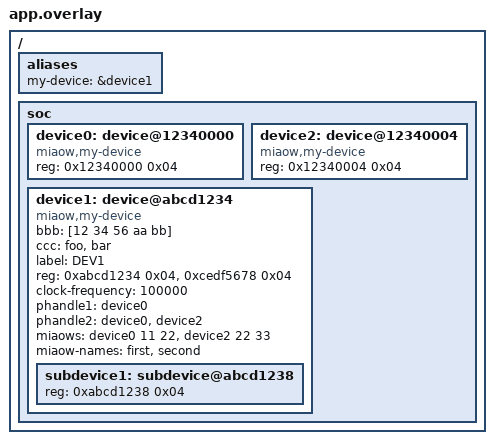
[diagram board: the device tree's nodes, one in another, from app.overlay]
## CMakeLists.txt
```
# SPDX-License-Identifier: Apache-2.0

cmake_minimum_required(VERSION 3.20.0)
set(BOARD fk743m5_xih6)
set(BOARD_FLASH_RUNNER jlink)
set(BOARD_DEBUG_RUNNER jlink)
set(BOARD_RUNNER_ARGS_jlink
    "--loader=BankAddr=0x90000000&Loader=CLK@PF10_nCS@PG6_D0@PF8_D1@PF9_D2@PF7_D3@PF6"
    CACHE STRING "Extra J-Link runner args" FORCE)
find_package(Zephyr REQUIRED HINTS $ENV{ZEPHYR_BASE})
find_package(Python3 REQUIRED COMPONENTS Interpreter)

project(devicetree LANGUAGES C)
target_sources(app PRIVATE ${CMAKE_SOURCE_DIR}/src/main.c)

# The code below locates the git index file for this repository and adds it as a dependency for
# the application VERSION file so that if the repo has a new commit added, even if no files in
# the build have changed, the application version file will be regenerated with the new git commit
find_package(Git QUIET)
if(GIT_FOUND)
  execute_process(
    COMMAND ${GIT_EXECUTABLE} rev-parse --absolute-git-dir
    WORKING_DIRECTORY .
    OUTPUT_VARIABLE application_git_dir
    OUTPUT_STRIP_TRAILING_WHITESPACE
    ERROR_STRIP_TRAILING_WHITESPACE
    ERROR_VARIABLE stderr
    RESULT_VARIABLE return_code
  )
  # If there is an error e.g. it is not a git repo, we just silently ignore it and continue
  # without a dependency, this will be the case with freestanding applications.
  if(NOT return_code)
    if(NOT "${stderr}" STREQUAL "")
      message(WARNING "Application build version git rev-parse warned: ${stderr}")
    endif()

    set_property(TARGET app_version_h PROPERTY APP_VERSION_DEPENDS ${application_git_dir}/index)
  endif()
endif()

# Update VS Code debug settings via workspace setup script.
# Run this after final zephyr.elf is linked (not after app library build).
set(VSCODE_SETUP_SCRIPT ${ZEPHYR_BASE}/../.vscode/setup.py)
if(EXISTS ${VSCODE_SETUP_SCRIPT})
  get_filename_component(VSCODE_ARM_TOOLCHAIN_PATH ${CMAKE_GDB} DIRECTORY)

  set(VSCODE_JLINK_DEVICE "")
  set(VSCODE_JLINK_LOADER "")
  get_property(VSCODE_JLINK_ARGS GLOBAL PROPERTY BOARD_RUNNER_ARGS_jlink)

  foreach(arg IN LISTS VSCODE_JLINK_ARGS)
    if(arg MATCHES "^--device=(.*)$")
      set(VSCODE_JLINK_DEVICE ${CMAKE_MATCH_1})
    elseif(arg MATCHES "^--loader=(.*)$")
      set(VSCODE_JLINK_LOADER ${CMAKE_MATCH_1})
    endif()
  endforeach()

  if(VSCODE_JLINK_LOADER)
    set(VSCODE_JLINK_DEVICE_FULL "${VSCODE_JLINK_DEVICE}?${VSCODE_JLINK_LOADER}")
  else()
    set(VSCODE_JLINK_DEVICE_FULL ${VSCODE_JLINK_DEVICE})
  endif()

  set(VSCODE_SETUP_STAMP ${CMAKE_BINARY_DIR}/.vscode_setup.stamp)
  add_custom_command(
    OUTPUT ${VSCODE_SETUP_STAMP}
    COMMAND ${Python3_EXECUTABLE} ${VSCODE_SETUP_SCRIPT}
      --app-path ${CMAKE_CURRENT_SOURCE_DIR}
      --build-path ${CMAKE_BINARY_DIR}
      --toolchain-path ${VSCODE_ARM_TOOLCHAIN_PATH}
      --gdb-path ${CMAKE_GDB}
      --device ${VSCODE_JLINK_DEVICE_FULL}
      --launch-json ${ZEPHYR_BASE}/../.vscode/launch.json
    COMMAND ${CMAKE_COMMAND} -E touch ${VSCODE_SETUP_STAMP}
    DEPENDS ${CMAKE_BINARY_DIR}/zephyr/zephyr.elf ${VSCODE_SETUP_SCRIPT}
    COMMENT "Run .vscode/setup.py to update launch.json and build symlink"
    VERBATIM
  )
  add_custom_target(vscode_setup_symlink ALL DEPENDS ${VSCODE_SETUP_STAMP})
endif()
```

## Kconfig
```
# SPDX-License-Identifier: Apache-2.0

mainmenu "03-devicetree"

# Your application configuration options go here

# Sources Kconfig.zephyr in the Zephyr root directory.
#
# Note: All 'source' statements work relative to the Zephyr root directory (due
# to the $srctree environment variable being set to $ZEPHYR_BASE). If you want
# to 'source' relative to the current Kconfig file instead, use 'rsource' (or a
# path relative to the Zephyr root).
source "Kconfig.zephyr"

menu "My Application Settings"

endmenu
```

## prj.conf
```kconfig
CONFIG_STD_C23=y
CONFIG_GNU_C_EXTENSIONS=y
CONFIG_SPEED_OPTIMIZATIONS=y
CONFIG_STM32_ENABLE_DEBUG_SLEEP_STOP=y

CONFIG_FPU=y
CONFIG_GPIO=y

CONFIG_LOG=y
CONFIG_LOG_RUNTIME_FILTERING=y
CONFIG_LOG_BACKEND_SWO=y
CONFIG_LOG_BACKEND_SWO_FREQ_HZ=50000000

CONFIG_BINDESC=y
CONFIG_BINDESC_DEFINE=y
CONFIG_BINDESC_DEFINE_VERSION=y
CONFIG_BINDESC_KERNEL_VERSION_STRING=y
CONFIG_BINDESC_KERNEL_VERSION_MAJOR=y
CONFIG_BINDESC_KERNEL_VERSION_MINOR=y
CONFIG_BINDESC_KERNEL_VERSION_PATCHLEVEL=y
CONFIG_BINDESC_KERNEL_VERSION_NUMBER=y
CONFIG_BINDESC_KERNEL_BUILD_VERSION=y
CONFIG_BINDESC_APP_VERSION_STRING=y
CONFIG_BINDESC_APP_VERSION_MAJOR=y
CONFIG_BINDESC_APP_VERSION_MINOR=y
CONFIG_BINDESC_APP_VERSION_PATCHLEVEL=y
CONFIG_BINDESC_APP_VERSION_NUMBER=y
CONFIG_BINDESC_APP_BUILD_VERSION=y
CONFIG_BINDESC_DEFINE_BUILD_TIME=y
CONFIG_BINDESC_BUILD_TIME_YEAR=y
CONFIG_BINDESC_BUILD_TIME_MONTH=y
CONFIG_BINDESC_BUILD_TIME_DAY=y
CONFIG_BINDESC_BUILD_TIME_HOUR=y
CONFIG_BINDESC_BUILD_TIME_MINUTE=y
CONFIG_BINDESC_BUILD_TIME_SECOND=y
CONFIG_BINDESC_BUILD_TIME_UNIX=y
CONFIG_BINDESC_BUILD_DATE_TIME_STRING=y
CONFIG_BINDESC_BUILD_DATE_STRING=y
CONFIG_BINDESC_BUILD_TIME_STRING=y
CONFIG_BINDESC_DEFINE_HOST_INFO=y
CONFIG_BINDESC_HOST_NAME=y
CONFIG_BINDESC_C_COMPILER_NAME=y
CONFIG_BINDESC_C_COMPILER_VERSION=y
CONFIG_BINDESC_CXX_COMPILER_NAME=y
CONFIG_BINDESC_CXX_COMPILER_VERSION=y
CONFIG_BINDESC_READ=y
CONFIG_BINDESC_READ_RAM=y
CONFIG_BINDESC_READ_MEMORY_MAPPED_FLASH=y
CONFIG_BINDESC_READ_FLASH=y
```

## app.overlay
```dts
/ {
	aliases {
		my-device = &device1;
	};

	soc {
		device0: device@12340000 {
			compatible = "miaow,my-device";
			#miaow-cells = <2>;
			reg = <0x12340000 0x04>;
		};

		device2: device@12340004 {
			compatible = "miaow,my-device";
			#miaow-cells = <2>;
			reg = <0x12340004 0x04>;
		};

		device1: device@abcd1234 {
			#address-cells = <1>;
    			#size-cells = <1>;
			#miaow-cells = <2>;

			compatible = "miaow,my-device";
			bbb = [12 34 56 aa bb];
			ccc = "foo", "bar";
			
                        label = "DEV1";
			reg = <0xabcd1234 0x04>, <0xcedf5678 0x04>;
			status = "okay";
			clock-frequency = <100000>;

			phandle1 = <&device0>;
			phandle2 = <&device0 &device2>;
			miaows = <&device0 11 22>, <&device2 22 33>;
			miaow-names = "first", "second";
			
			subdevice1: subdevice@abcd1238 {
				#phandle-miaow-cells = <2>;
				reg = <0xabcd1238 0x04>;
			};
		};
	};
};
```

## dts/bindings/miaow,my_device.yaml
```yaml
description: My custom device
compatible: "miaow,my-device"
miaow-cells:
  - c1
  - c2

include: [base.yaml]

properties:
  bbb:
    type: uint8-array
    description: My custom byte array property
    required: false

  ccc:
    type: string-array
    description: My custom string array property
    required: false

  clock-frequency:
    type: int
    description: Clock frequency for the device
    required: false
  
  phandle1:
    type: phandle
    description: A phandle property pointing to another node
    required: false
  
  phandle2:
    type: phandles
    description: An array of phandles pointing to other nodes
    required: false
  
  miaows:
    type: phandle-array
    description: An array of phandles pointing to other nodes
    required: false
  
  miaow-names:
    type: string-array
    description: An array of named phandles pointing to other nodes
    required: false
```

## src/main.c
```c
/*
 * Copyright (C) 2026, Miaow - All Rights Reserved
 *
 * SPDX-License-Identifier: GPL-3.0-or-later
 */
#include <stdio.h>
#include <zephyr/kernel.h>
#include <zephyr/bindesc.h>
#include <zephyr/logging/log.h>
#include <zephyr/devicetree.h>

LOG_MODULE_REGISTER(03_devicetree, LOG_LEVEL_INF);

/* Define the device node using one of the following methods:
 * 1. DT_PATH: path to the device node in the device tree
 * 2. DT_NODELABEL: node label defined in the device tree
 * 3. DT_ALIAS: alias defined in the device tree for the node
 * 4. DT_INST: instance of a compatible device. instance have no gurantee to be stable
 *
 * Uncomment one of the following lines to define MY_DEVICE_NODE accordingly.
 */
#define MY_DEVICE_NODE DT_PATH(soc, device_abcd1234)
// #define MY_DEVICE_NODE DT_NODELABEL(device1)
// #define MY_DEVICE_NODE DT_ALIAS(my_device)
// #define MY_DEVICE_NODE DT_INST(0, miaow_my_device)
// #define MY_DEVICE_NODE DT_CHILD(DT_PATH(soc), device_abcd1234)
// #define MY_DEVICE_NODE DT_PARENT(DT_PATH(soc, device_abcd1234, subdevice_abcd1238))

/**
 * @brief Print the message of the day (MOTD) using built-in descriptors.
 *
 * This function retrieves and prints various build and host information
 * using built-in descriptors defined in the Zephyr build system. It includes
 * details about the Zephyr version, application version, build time, and host
 * information such as compiler details.
 */
void print_motd()
{
	/* Builtin descriptors */
	printk("Zephyr version %s\n\tmajor:minor %u:%u\n\tnumber %u\n\tpatch %u\n\tbuild %s\n", BINDESC_GET_STR(kernel_version_string),
		BINDESC_GET_UINT(kernel_version_major), BINDESC_GET_UINT(kernel_version_minor),
		BINDESC_GET_UINT(kernel_version_number), BINDESC_GET_UINT(kernel_version_patchlevel),
		BINDESC_GET_STR(kernel_build_version)
	);
	printk("App version %s\n\tmajor:minor %u:%u\n\tnumber %u\n\tpatch %u\n\tbuild %s\n", BINDESC_GET_STR(app_version_string),
		BINDESC_GET_UINT(app_version_major), BINDESC_GET_UINT(app_version_minor),
		BINDESC_GET_UINT(app_version_number), BINDESC_GET_UINT(app_version_patchlevel),
		BINDESC_GET_STR(app_build_version)
	);
	printk("Build time %s\n\tdate %s\n\ttime %s\n\tunix %u\n\tyear %u\n\tmonth %u\n\tday %u\n\thour %u\n\tminute %u\n\tsecond %u\n",
		BINDESC_GET_STR(build_date_time_string),
		BINDESC_GET_STR(build_date_string),
		BINDESC_GET_STR(build_time_string),
		BINDESC_GET_UINT(build_time_unix),
		BINDESC_GET_UINT(build_time_year), BINDESC_GET_UINT(build_time_month), BINDESC_GET_UINT(build_time_day),
		BINDESC_GET_UINT(build_time_hour), BINDESC_GET_UINT(build_time_minute), BINDESC_GET_UINT(build_time_second)
	);
	printk("Host info\n\thost %s\n\tcc %s %s\n\tc++ %s %s\n",
		BINDESC_GET_STR(host_name),
		BINDESC_GET_STR(c_compiler_name), BINDESC_GET_STR(c_compiler_version),
		BINDESC_GET_STR(cxx_compiler_name), BINDESC_GET_STR(cxx_compiler_version)
	);
}

/**
 * @brief Check for the presence of specific properties in the device node.
 */
void check_prop()
{
	printk("has prop clock_frequency: %d\n", DT_NODE_HAS_PROP(MY_DEVICE_NODE, clock_frequency));
	printk("has prop not_a_prop: %d\n", DT_NODE_HAS_PROP(MY_DEVICE_NODE, not_a_prop));
	printk("ccc prop has index 1: %d\n", DT_PROP_HAS_IDX(MY_DEVICE_NODE, ccc, 1));
	printk("ccc prop has index 2: %d\n", DT_PROP_HAS_IDX(MY_DEVICE_NODE, ccc, 2));
}

/**
 * @brief Retrieve and print properties of the device node.
 */
void get_prop()
{
	const char compatible[] = DT_PROP(MY_DEVICE_NODE, compatible);
	const char label[] = DT_PROP(MY_DEVICE_NODE, label);
	const int reg[] = DT_PROP(MY_DEVICE_NODE, reg);
	const char status[] = DT_PROP(MY_DEVICE_NODE, status);
	const unsigned char b[] = DT_PROP(MY_DEVICE_NODE, bbb);
	const size_t b_item_count = DT_PROP_LEN(MY_DEVICE_NODE, bbb);
	const char *const c[] = DT_PROP(MY_DEVICE_NODE, ccc);
	const size_t c_item_count = DT_PROP_LEN(MY_DEVICE_NODE, ccc);

	printk("compatible=%s\n", compatible);
	printk("label=%s\n", label);

	printk("reg[]=");
	for (size_t i = 0; i < ARRAY_SIZE(reg); i++)
		printk("0x%x, ", reg[i]);
	printk("\n");

	printk("status=%s\n", status);

	printk("b[]=");
	for (size_t i = 0; i < b_item_count; i++)
		printk("%x, ", (int)b[i]);
	printk("\n");

	printk("c[]=");
	for (size_t i = 0; i < c_item_count; i++)
		printk("%s ", c[i]);
	printk("\n");
}

/**
 * @brief Retrieve and print the 'reg' properties of the device node.
 */
void reg_prop()
{
	size_t reg_count = DT_NUM_REGS(MY_DEVICE_NODE);
	printk("Number of reg blocks = %d\n", reg_count);
	uint32_t addr[] = {DT_REG_ADDR_BY_IDX(MY_DEVICE_NODE, 0), DT_REG_ADDR_BY_IDX(MY_DEVICE_NODE, 1)};
	uint32_t size[] = {DT_REG_SIZE_BY_IDX(MY_DEVICE_NODE, 0), DT_REG_SIZE_BY_IDX(MY_DEVICE_NODE, 1)};
	printk("reg[0].addr = 0x%x, .size = 0x%x\n", addr[0], size[0]);
	printk("reg[1].addr = 0x%x, .size = 0x%x\n", addr[1], size[1]);
}

/**
 * @brief Retrieve a device using a phandle property and check if it is ready.
 */
void phandle_prop()
{
	char *node1 = STRINGIFY(DT_PHANDLE(MY_DEVICE_NODE, phandle1));
	printk("phandle1 points to node %s\n", node1);
	
	char *node2 = STRINGIFY(DT_PHANDLE_BY_IDX(MY_DEVICE_NODE, phandle2, 1));
	printk("phandle2[1] points to node %s\n", node2);

	char *node3 = STRINGIFY(DT_PHANDLE_BY_NAME(MY_DEVICE_NODE, miaows, first));
	printk("miaows[first] points to node %s\n", node3);

	int c1_value = DT_PHA_BY_IDX(MY_DEVICE_NODE, miaows, 1, c1);
	printk("miaows[1].c1 = %d\n", c1_value);

	int flag = DT_PHA_HAS_CELL_AT_IDX(MY_DEVICE_NODE, miaows, 1, c2);
	printk("does miaows[1] have a cell named c2? %d\n", flag);
}

int main(void)
{
	print_motd();

	LOG_INF("Init done!");
	
	/* Check if the device node has certain properties and print their values */
	LOG_INF("Check prop of device node %s...", STRINGIFY(MY_DEVICE_NODE));
	check_prop();
	k_msleep(100);

	/* Retrieve and print properties of the device node */
	LOG_INF("Retrieve prop of device node %s...", STRINGIFY(MY_DEVICE_NODE));
	get_prop();
	k_msleep(100);

	/* Reg properties of the device node */
	LOG_INF("Reg properties of device node %s...", STRINGIFY(MY_DEVICE_NODE));
	reg_prop();
	k_msleep(100);

	/* Phandle properties of the device node */
	LOG_INF("Phandle properties of device node %s...", STRINGIFY(MY_DEVICE_NODE));
	phandle_prop();
	k_msleep(100);

	return 0;
}
```
